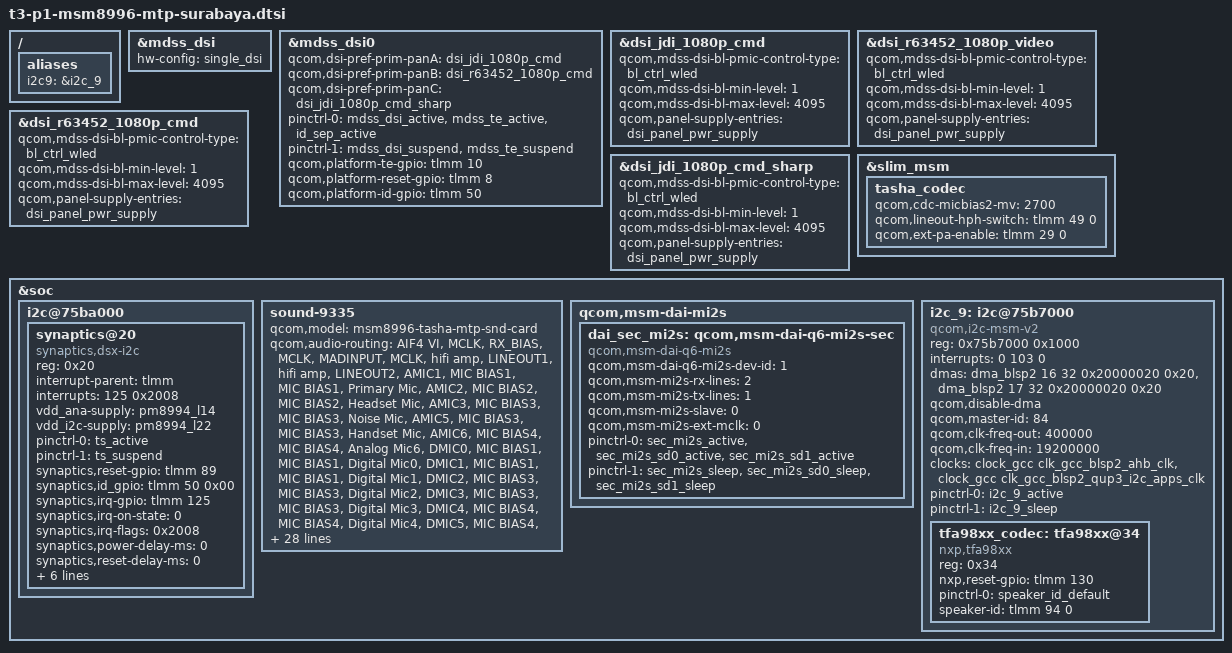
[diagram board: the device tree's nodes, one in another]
/* It inherits from msm8996-mtp.dtsi */

#include "t3-p1-msm8996-mdss-panels-surabaya.dtsi"

/ {
	aliases {
		i2c9 = &i2c_9;
	};
};

&mdss_dsi {
	hw-config = "single_dsi";
};

&mdss_dsi0 {
	qcom,dsi-pref-prim-panA = <&dsi_jdi_1080p_cmd>;			/*t3 p1*/
	qcom,dsi-pref-prim-panB = <&dsi_r63452_1080p_cmd>;	 /*t3 p2gpio low*/
	//qcom,dsi-pref-prim-panB = <&dsi_r63452_1080p_video>;
	qcom,dsi-pref-prim-panC = <&dsi_jdi_1080p_cmd_sharp>;  /*t3 p2gpio high*/
	pinctrl-names = "mdss_default", "mdss_sleep";
	pinctrl-0 = <&mdss_dsi_active &mdss_te_active &id_sep_active>;
	pinctrl-1 = <&mdss_dsi_suspend &mdss_te_suspend>;
	qcom,platform-te-gpio = <&tlmm 10 0>;
	qcom,platform-reset-gpio = <&tlmm 8 0>;
	qcom,platform-id-gpio = <&tlmm 50 0>;
};

&dsi_jdi_1080p_cmd {
	qcom,mdss-dsi-bl-pmic-control-type = "bl_ctrl_wled";
	qcom,mdss-dsi-bl-min-level = <1>;
	qcom,mdss-dsi-bl-max-level = <4095>;
	qcom,panel-supply-entries = <&dsi_panel_pwr_supply>;
};

&dsi_r63452_1080p_video{
	qcom,mdss-dsi-bl-pmic-control-type = "bl_ctrl_wled";
	qcom,mdss-dsi-bl-min-level = <1>;
	qcom,mdss-dsi-bl-max-level = <4095>;
	qcom,panel-supply-entries = <&dsi_panel_pwr_supply>;
};

&dsi_r63452_1080p_cmd {
	qcom,mdss-dsi-bl-pmic-control-type = "bl_ctrl_wled";
	qcom,mdss-dsi-bl-min-level = <1>;
	qcom,mdss-dsi-bl-max-level = <4095>;
	qcom,panel-supply-entries = <&dsi_panel_pwr_supply>;
};

&dsi_jdi_1080p_cmd_sharp {
	qcom,mdss-dsi-bl-pmic-control-type = "bl_ctrl_wled";
	qcom,mdss-dsi-bl-min-level = <1>;
	qcom,mdss-dsi-bl-max-level = <4095>;
	qcom,panel-supply-entries = <&dsi_panel_pwr_supply>;
};



&slim_msm {
	tasha_codec {
		qcom,cdc-micbias2-mv = <2700>;

		qcom,lineout-hph-switch = <&tlmm 49 0>;
		qcom,ext-pa-enable = <&tlmm 29 0>;
	};
};

&soc {
	i2c@75ba000 {
		synaptics@20 {
			compatible = "synaptics,dsx-i2c";
			reg = <0x20>;
			interrupt-parent = <&tlmm>;
			interrupts = <125 0x2008>;
			vdd_ana-supply = <&pm8994_l14>;
			vdd_i2c-supply = <&pm8994_l22>;
			//synaptics,pwr-reg-name = "vdd_ana";
			//synaptics,bus-reg-name = "vcc_i2c";
			pinctrl-names = "pmx_ts_active", "pmx_ts_suspend";
			pinctrl-0 = <&ts_active>;
			pinctrl-1 = <&ts_suspend>;
			synaptics,reset-gpio = <&tlmm 89 0x00>;
			synaptics,id_gpio = <&tlmm 50 0x00>;
			synaptics,irq-gpio = <&tlmm 125 0x2008>;
			synaptics,irq-on-state = <0>;
			synaptics,irq-flags = <0x2008>; /* IRQF_ONESHOT | IRQF_TRIGGER_LOW */
			synaptics,power-delay-ms = <0>;
			synaptics,reset-delay-ms = <0>;
			synaptics,reset-on-state = <0>;
			synaptics,reset-active-ms = <0>;
			synaptics,x-flip;
			synaptics,y-flip;
			//synaptics,disable-gpios;
			/* Underlying clocks used by secure touch */
			clock-names = "iface_clk", "core_clk";
			clocks = <&clock_gcc clk_gcc_blsp2_ahb_clk>,
				 <&clock_gcc clk_gcc_blsp2_qup6_i2c_apps_clk>;
		};
	};

	sound-9335 {
		qcom,model = "msm8996-tasha-mtp-snd-card";

		qcom,audio-routing =
			"AIF4 VI", "MCLK",
			"RX_BIAS", "MCLK",
			"MADINPUT", "MCLK",
			"hifi amp", "LINEOUT1",
			"hifi amp", "LINEOUT2",
			"AMIC1", "MIC BIAS1",
			"MIC BIAS1", "Primary Mic",
			"AMIC2", "MIC BIAS2",
			"MIC BIAS2", "Headset Mic",
			"AMIC3", "MIC BIAS3",
			"MIC BIAS3", "Noise Mic",
			"AMIC5", "MIC BIAS3",
			"MIC BIAS3", "Handset Mic",
			"AMIC6", "MIC BIAS4",
			"MIC BIAS4", "Analog Mic6",
			"DMIC0", "MIC BIAS1",
			"MIC BIAS1", "Digital Mic0",
			"DMIC1", "MIC BIAS1",
			"MIC BIAS1", "Digital Mic1",
			"DMIC2", "MIC BIAS3",
			"MIC BIAS3", "Digital Mic2",
			"DMIC3", "MIC BIAS3",
			"MIC BIAS3", "Digital Mic3",
			"DMIC4", "MIC BIAS4",
			"MIC BIAS4", "Digital Mic4",
			"DMIC5", "MIC BIAS4",
			"MIC BIAS4", "Digital Mic5",
			"SpkrLeft IN", "SPK1 OUT",
			"SpkrRight IN", "SPK2 OUT";

		asoc-cpu = <&dai_pri_auxpcm>, <&dai_sec_auxpcm>,
				<&dai_hdmi>, <&dai_sec_mi2s>,
				<&sb_0_rx>, <&sb_0_tx>, <&sb_1_rx>, <&sb_1_tx>,
				<&sb_2_rx>, <&sb_2_tx>, <&sb_3_rx>, <&sb_3_tx>,
				<&sb_4_rx>, <&sb_4_tx>, <&sb_5_tx>, <&afe_pcm_rx>,
				<&afe_pcm_tx>, <&afe_proxy_rx>, <&afe_proxy_tx>,
				<&incall_record_rx>, <&incall_record_tx>,
				<&incall_music_rx>, <&incall_music2_rx>,
				<&sb_5_rx>, <&sb_6_rx>;
		asoc-cpu-names = "msm-dai-q6-auxpcm.1", "msm-dai-q6-auxpcm.2",
				"msm-dai-q6-hdmi.8", "msm-dai-q6-mi2s.1",
				"msm-dai-q6-dev.16384", "msm-dai-q6-dev.16385",
				"msm-dai-q6-dev.16386", "msm-dai-q6-dev.16387",
				"msm-dai-q6-dev.16388", "msm-dai-q6-dev.16389",
				"msm-dai-q6-dev.16390", "msm-dai-q6-dev.16391",
				"msm-dai-q6-dev.16392", "msm-dai-q6-dev.16393",
				"msm-dai-q6-dev.16395", "msm-dai-q6-dev.224",
				"msm-dai-q6-dev.225", "msm-dai-q6-dev.241",
				"msm-dai-q6-dev.240", "msm-dai-q6-dev.32771",
				"msm-dai-q6-dev.32772", "msm-dai-q6-dev.32773",
				"msm-dai-q6-dev.32770", "msm-dai-q6-dev.16394",
				"msm-dai-q6-dev.16396";

		qcom,msm-mbhc-hphl-swh = <1>;
		qcom,msm-mbhc-gnd-swh = <0>;
		asoc-codec = <&stub_codec>, <&tfa98xx_codec>;
		asoc-codec-names = "msm-stub-codec.1", "tfa98xx.5-0034";
	};

	qcom,msm-dai-mi2s {
		dai_sec_mi2s: qcom,msm-dai-q6-mi2s-sec {
			compatible = "qcom,msm-dai-q6-mi2s";
			qcom,msm-dai-q6-mi2s-dev-id = <1>;
			qcom,msm-mi2s-rx-lines = <2>;
			qcom,msm-mi2s-tx-lines = <1>;
			qcom,msm-mi2s-slave = <0>;
			qcom,msm-mi2s-ext-mclk = <0>;
			pinctrl-names = "default", "sleep";
			pinctrl-0 = <&sec_mi2s_active &sec_mi2s_sd0_active &sec_mi2s_sd1_active>;
			pinctrl-1 = <&sec_mi2s_sleep &sec_mi2s_sd0_sleep &sec_mi2s_sd1_sleep>;
		};

	};

	i2c_9: i2c@75b7000 { /* BLSP2 QUP3 */
		compatible = "qcom,i2c-msm-v2";
		#address-cells = <1>;
		#size-cells = <0>;
		reg-names = "qup_phys_addr";
		reg = <0x75b7000 0x1000>;
		interrupt-names = "qup_irq";
		interrupts = <0 103 0>;
		dmas = <&dma_blsp2 16 32 0x20000020 0x20>,
			<&dma_blsp2 17 32 0x20000020 0x20>;
		dma-names = "tx", "rx";
		qcom,disable-dma;
		qcom,master-id = <84>;
		qcom,clk-freq-out = <400000>;
		qcom,clk-freq-in  = <19200000>;
		clock-names = "iface_clk", "core_clk";
		clocks = <&clock_gcc clk_gcc_blsp2_ahb_clk>,
			<&clock_gcc clk_gcc_blsp2_qup3_i2c_apps_clk>;
		pinctrl-names = "i2c_active", "i2c_sleep";
		pinctrl-0 = <&i2c_9_active>;
		pinctrl-1 = <&i2c_9_sleep>;
	};

	i2c@75b7000 {
		tfa98xx_codec: tfa98xx@34 {
			compatible = "nxp,tfa98xx";
			reg = <0x34>;
			nxp,reset-gpio = <&tlmm 130 0>;
			pinctrl-names = "default";
			pinctrl-0 = <&speaker_id_default>;
			speaker-id = <&tlmm 94 0>;
		};
	};
};
